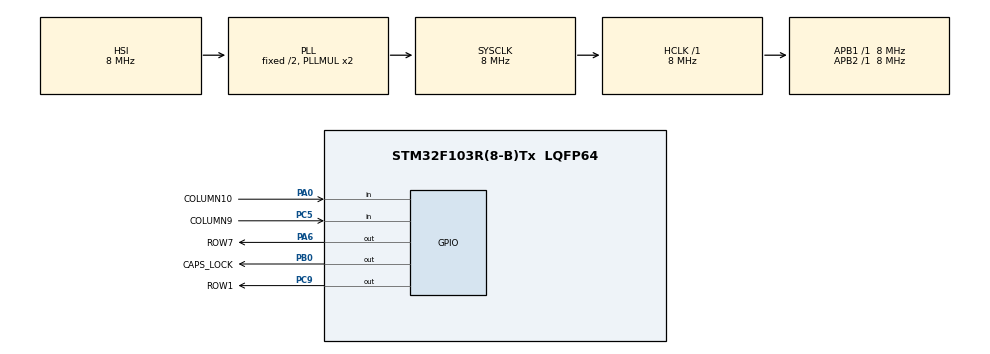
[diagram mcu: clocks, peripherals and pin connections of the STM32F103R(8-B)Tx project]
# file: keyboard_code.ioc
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Mcu.Family=STM32F1
Mcu.Name=STM32F103R(8-B)Tx
Mcu.Package=LQFP64
NVIC.PriorityGroup=NVIC_PRIORITYGROUP_4
PA0-WKUP.GPIO_Label=COLUMN10
PA0-WKUP.GPIO_PuPd=GPIO_PULLDOWN
PA0-WKUP.Signal=GPIO_Input
PA13.Mode=Trace_Asynchronous_SW
PA13.Signal=SYS_JTMS-SWDIO
PA14.Mode=Trace_Asynchronous_SW
PA14.Signal=SYS_JTCK-SWCLK
PA6.GPIO_Label=ROW7
PA6.GPIO_PuPd=GPIO_PULLDOWN
PA6.GPIO_Speed=GPIO_SPEED_FREQ_HIGH
PA6.PinState=GPIO_PIN_SET
PA6.Signal=GPIO_Output
PB0.GPIO_Label=CAPS_LOCK
PB0.GPIO_ModeDefaultOutputPP=GPIO_MODE_OUTPUT_PP
PB0.GPIO_PuPd=GPIO_PULLDOWN
PB0.GPIO_Speed=GPIO_SPEED_FREQ_HIGH
PB0.PinState=GPIO_PIN_SET
PB0.Signal=GPIO_Output
PB3.Mode=Trace_Asynchronous_SW
PB3.Signal=SYS_JTDO-TRACESWO
PC5.GPIO_Label=COLUMN9
PC5.GPIO_PuPd=GPIO_PULLDOWN
PC5.Signal=GPIO_Input
PC9.GPIO_Label=ROW1
PC9.GPIO_ModeDefaultOutputPP=GPIO_MODE_OUTPUT_PP
PC9.GPIO_PuPd=GPIO_PULLDOWN
PC9.PinState=GPIO_PIN_SET
PC9.Signal=GPIO_Output
ProjectManager.HeapSize=0x200
ProjectManager.StackSize=0x400
ProjectManager.TargetToolchain=STM32CubeIDE
RCC.AHBFreq_Value=8000000
RCC.APB1Freq_Value=8000000
RCC.APB1TimFreq_Value=8000000
RCC.APB2Freq_Value=8000000
RCC.APB2TimFreq_Value=8000000
RCC.HCLKFreq_Value=8000000
RCC.SYSCLKFreq_VALUE=8000000
RCC.SYSCLKSource=RCC_SYSCLKSOURCE_PLLCLK
RCC.USBFreq_Value=8000000
board=custom

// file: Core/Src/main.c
/* USER CODE BEGIN Header */
/**
 ******************************************************************************
 * @file           : main.c
 * @brief          : Main program body
 ******************************************************************************
 * @attention
 *
 * Copyright (c) 2023 STMicroelectronics.
 * All rights reserved.
 *
 * This software is licensed under terms that can be found in the LICENSE file
 * in the root directory of this software component.
 * If no LICENSE file comes with this software, it is provided AS-IS.
 *
 ******************************************************************************
 */
/* USER CODE END Header */
#include "main.h"

/* USER CODE BEGIN Includes */
#include "../THE_APP/app_main.h"

/* USER CODE END Includes */

void SystemClock_Config(void);
static void MX_GPIO_Init(void);

int main(void)
{

  /* MCU Configuration--------------------------------------------------------*/

  /* Reset of all peripherals, Initializes the Flash interface and the Systick. */
  HAL_Init();

  /* Configure the system clock */
  SystemClock_Config();

  /* Initialize all configured peripherals */
  MX_GPIO_Init();

  /* Infinite loop */
  /* USER CODE BEGIN WHILE */
	while (1) {
		do_work();
    /* USER CODE END WHILE */

	}
}

void SystemClock_Config(void)
{
  RCC_OscInitTypeDef RCC_OscInitStruct = {0};
  RCC_ClkInitTypeDef RCC_ClkInitStruct = {0};

  /** Initializes the RCC Oscillators according to the specified parameters
  * in the RCC_OscInitTypeDef structure.
  */
  RCC_OscInitStruct.OscillatorType = RCC_OSCILLATORTYPE_HSI;
  RCC_OscInitStruct.HSIState = RCC_HSI_ON;
  RCC_OscInitStruct.HSICalibrationValue = RCC_HSICALIBRATION_DEFAULT;
  RCC_OscInitStruct.PLL.PLLState = RCC_PLL_ON;
  RCC_OscInitStruct.PLL.PLLSource = RCC_PLLSOURCE_HSI_DIV2;
  RCC_OscInitStruct.PLL.PLLMUL = RCC_PLL_MUL2;
  if (HAL_RCC_OscConfig(&RCC_OscInitStruct) != HAL_OK)
  {
    Error_Handler();
  }

  /** Initializes the CPU, AHB and APB buses clocks
  */
  RCC_ClkInitStruct.ClockType = RCC_CLOCKTYPE_HCLK|RCC_CLOCKTYPE_SYSCLK
                              |RCC_CLOCKTYPE_PCLK1|RCC_CLOCKTYPE_PCLK2;
  RCC_ClkInitStruct.SYSCLKSource = RCC_SYSCLKSOURCE_PLLCLK;
  RCC_ClkInitStruct.AHBCLKDivider = RCC_SYSCLK_DIV1;
  RCC_ClkInitStruct.APB1CLKDivider = RCC_HCLK_DIV1;
  RCC_ClkInitStruct.APB2CLKDivider = RCC_HCLK_DIV1;

  if (HAL_RCC_ClockConfig(&RCC_ClkInitStruct, FLASH_LATENCY_0) != HAL_OK)
  {
    Error_Handler();
  }
}

static void MX_GPIO_Init(void)
{
  GPIO_InitTypeDef GPIO_InitStruct = {0};

  /* GPIO Ports Clock Enable */
  __HAL_RCC_GPIOA_CLK_ENABLE();
  __HAL_RCC_GPIOC_CLK_ENABLE();
  __HAL_RCC_GPIOB_CLK_ENABLE();

  /*Configure GPIO pin Output Level */
  HAL_GPIO_WritePin(ROW7_GPIO_Port, ROW7_Pin, GPIO_PIN_SET);

  /*Configure GPIO pin Output Level */
  HAL_GPIO_WritePin(CAPS_LOCK_GPIO_Port, CAPS_LOCK_Pin, GPIO_PIN_SET);

  /*Configure GPIO pin Output Level */
  HAL_GPIO_WritePin(ROW1_GPIO_Port, ROW1_Pin, GPIO_PIN_SET);

  /*Configure GPIO pin : COLUMN10_Pin */
  GPIO_InitStruct.Pin = COLUMN10_Pin;
  GPIO_InitStruct.Mode = GPIO_MODE_INPUT;
  GPIO_InitStruct.Pull = GPIO_PULLDOWN;
  HAL_GPIO_Init(COLUMN10_GPIO_Port, &GPIO_InitStruct);

  /*Configure GPIO pin : ROW7_Pin */
  GPIO_InitStruct.Pin = ROW7_Pin;
  GPIO_InitStruct.Mode = GPIO_MODE_OUTPUT_PP;
  GPIO_InitStruct.Pull = GPIO_PULLDOWN;
  GPIO_InitStruct.Speed = GPIO_SPEED_FREQ_HIGH;
  HAL_GPIO_Init(ROW7_GPIO_Port, &GPIO_InitStruct);

  /*Configure GPIO pin : COLUMN9_Pin */
  GPIO_InitStruct.Pin = COLUMN9_Pin;
  GPIO_InitStruct.Mode = GPIO_MODE_INPUT;
  GPIO_InitStruct.Pull = GPIO_PULLDOWN;
  HAL_GPIO_Init(COLUMN9_GPIO_Port, &GPIO_InitStruct);

  /*Configure GPIO pin : CAPS_LOCK_Pin */
  GPIO_InitStruct.Pin = CAPS_LOCK_Pin;
  GPIO_InitStruct.Mode = GPIO_MODE_OUTPUT_PP;
  GPIO_InitStruct.Pull = GPIO_PULLDOWN;
  GPIO_InitStruct.Speed = GPIO_SPEED_FREQ_HIGH;
  HAL_GPIO_Init(CAPS_LOCK_GPIO_Port, &GPIO_InitStruct);

  /*Configure GPIO pin : ROW1_Pin */
  GPIO_InitStruct.Pin = ROW1_Pin;
  GPIO_InitStruct.Mode = GPIO_MODE_OUTPUT_PP;
  GPIO_InitStruct.Pull = GPIO_PULLDOWN;
  GPIO_InitStruct.Speed = GPIO_SPEED_FREQ_LOW;
  HAL_GPIO_Init(ROW1_GPIO_Port, &GPIO_InitStruct);

}

void Error_Handler(void)
{
	__disable_irq();
	while (1) {
	}
}
